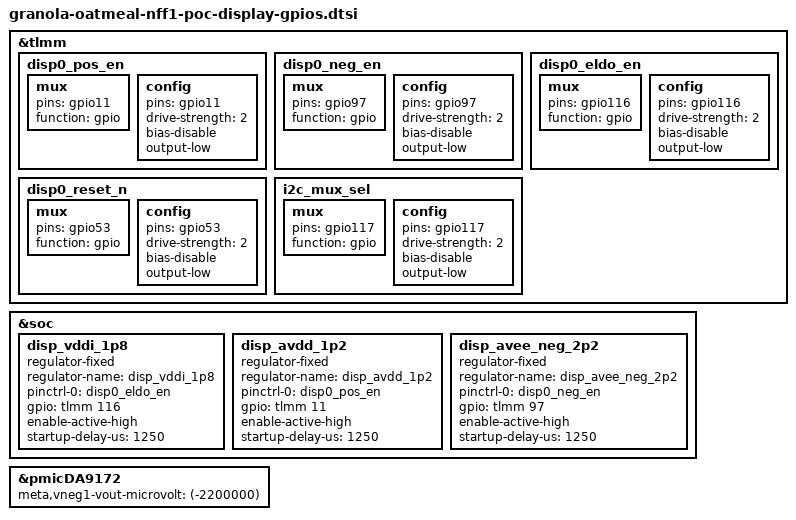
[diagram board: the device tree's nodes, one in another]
&tlmm {
	disp0_pos_en: disp0_pos_en {
		mux {
			pins = "gpio11";
			function = "gpio";
		};

		config {
			pins = "gpio11";
			drive-strength = <2>;
			bias-disable;
			output-low;
		};
	};

	disp0_neg_en: disp0_neg_en {
		mux {
			pins = "gpio97";
			function = "gpio";
		};

		config {
			pins = "gpio97";
			drive-strength = <2>;
			bias-disable;
			output-low;
		};
	};

	disp0_eldo_en: disp0_eldo_en {
		mux {
			pins = "gpio116";
			function = "gpio";
		};

		config {
			pins = "gpio116";
			drive-strength = <2>;
			bias-disable;
			output-low;
		};
	};

	disp0_reset_n: disp0_reset_n {
		mux {
			pins = "gpio53";
			function = "gpio";
		};

		config {
			pins = "gpio53";
			drive-strength = <2>;
			bias-disable;
			output-low;
		};
	};

	i2c_mux_sel: i2c_mux_sel {
		mux {
			pins = "gpio117";
			function = "gpio";
		};

		config {
			pins = "gpio117";
			drive-strength = <2>;
			bias-disable;
			output-low;
		};
	};
};

&soc {
	disp_vddi_1p8: disp_vddi_1p8 {
		compatible = "regulator-fixed";
		regulator-name = "disp_vddi_1p8";
		pinctrl-names = "default";
		pinctrl-0 = <&disp0_eldo_en>;
		gpio = <&tlmm 116 GPIO_ACTIVE_HIGH>;
		enable-active-high;
		startup-delay-us = <1250>;
		status = "okay";
	};

	disp_avdd_1p2: disp_avdd_1p2 {
		compatible = "regulator-fixed";
		regulator-name = "disp_avdd_1p2";
		pinctrl-names = "default";
		pinctrl-0 = <&disp0_pos_en>;
		gpio = <&tlmm 11 GPIO_ACTIVE_HIGH>;
		enable-active-high;
		startup-delay-us = <1250>;
		status = "okay";
	};

	disp_avee_neg_2p2: disp_avee_neg_2p2 {
		compatible = "regulator-fixed";
		regulator-name = "disp_avee_neg_2p2";
		pinctrl-names = "default";
		pinctrl-0 = <&disp0_neg_en>;
		gpio = <&tlmm 97 GPIO_ACTIVE_HIGH>;
		enable-active-high;
		startup-delay-us = <1250>;
		status = "okay";
	};
};

#include "granola-display-common.dtsi"

&pmicDA9172 {
	/* PMICs used for NFF1 build have VNEG1 VOUT programmed to -2V in OTP. */
	/* Override to -2.2V because that's what JBD2520 panels need. */
	meta,vneg1-vout-microvolt = <(-2200000)>;
};
